# ATmega8A register map
Vendor: Atmel; File version: 1.0
CPU: other r0p0, little endian, no MPU, no FPU, 4 interrupt priority bits
Registers are 8-bit, read-write, reset 0x0 unless marked. A register's access mark holds for its fields unless they carry their own. Offsets are from the block's base; [hi:lo] are bit positions; {n}, {i} and the like mark numbered series; 'fields as' and 'values as' point back to an identical list.

## EEPROM
Base 0x0000003C
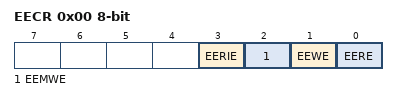
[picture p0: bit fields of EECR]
0x00 EECR — EEPROM Control Register
  [3] EERIE — EEPROM Ready Interrupt Enable
  [2] EEMWE — EEPROM Master Write Enable
  [1] EEWE — EEPROM Write Enable
  [0] EERE — EEPROM Read Enable
0x01 EEDR — EEPROM Data Register
0x02 EEAR 16-bit (reset mask 0xFF) — EEPROM Address Register Bytes

## EXINT — External Interrupts
Base 0x00000055
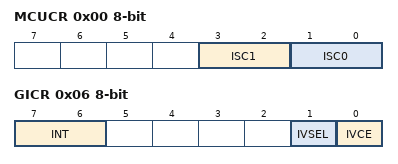
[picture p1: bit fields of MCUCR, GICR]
0x00 MCUCR — MCU Control Register
  [3:2] ISC1 — Interrupt Sense Control 1 Bits
    0=Low Level of INTX; 1=Any Logical Change of INTX; 2=Falling Edge of INTX; 3=Rising Edge of INTX
  [1:0] ISC0 — Interrupt Sense Control 0 Bits
    values as ISC1
0x05 GIFR — General Interrupt Flag Register
  [7:6] INTF — External Interrupt Flags
0x06 GICR — General Interrupt Control Register
  [7:6] INT — External Interrupt Request 1 Enable
  [1] IVSEL — Interrupt Vector Select
  [0] IVCE — Interrupt Vector Change Enable

## LOCKBIT — Lockbits
Base 0x00000000
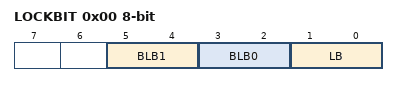
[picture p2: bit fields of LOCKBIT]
0x00 LOCKBIT
  [5:4] BLB1 — Boot Loader Protection Mode
    0=LPM_SPM_DISABLE (LPM and SPM prohibited in Boot Section); 1=LPM_DISABLE (LPM prohibited in Boot Section); 2=SPM_DISABLE (SPM prohibited in Boot Section); 3=NO_LOCK (No lock on SPM and LPM in Boot Section)
  [3:2] BLB0 — Boot Loader Protection Mode
    0=LPM_SPM_DISABLE (LPM and SPM prohibited in Application Section); 1=LPM_DISABLE (LPM prohibited in Application Section); 2=SPM_DISABLE (SPM prohibited in Application Section); 3=NO_LOCK (No lock on SPM and LPM in Application Section)
  [1:0] LB — Memory Lock
    0=PROG_VER_DISABLED (Further programming and verification disabled); 2=PROG_DISABLED (Further programming disabled); 3=NO_LOCK (No memory lock features enabled)

## PORTB — I/O Port
Base 0x00000036
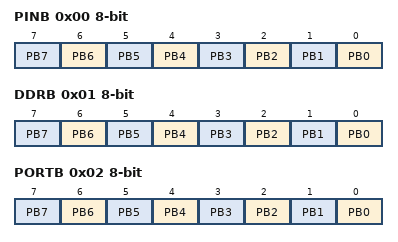
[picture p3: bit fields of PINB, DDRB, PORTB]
0x00 PINB — Port B Input Pins
  [n] PB{n} (n=0..7) — Pin B{n}
0x01 DDRB — Port B Data Direction Register
  [n] PB{n} (n=0..7) — Pin B{n}
0x02 PORTB — Port B Data Register
  [n] PB{n} (n=0..7) — Pin B{n}

## PORTC — I/O Port
Base 0x00000033
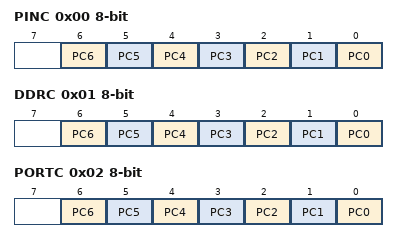
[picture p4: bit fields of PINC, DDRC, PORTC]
0x00 PINC — Port C Input Pins
  [n] PC{n} (n=0..6) — Pin C{n}
0x01 DDRC — Port C Data Direction Register
  [n] PC{n} (n=0..6) — Pin C{n}
0x02 PORTC — Port C Data Register
  [n] PC{n} (n=0..6) — Pin C{n}

## PORTD — I/O Port
Base 0x00000030
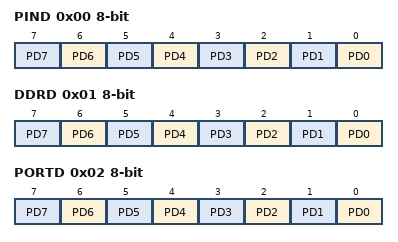
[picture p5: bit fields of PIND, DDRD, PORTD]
0x00 PIND — Port D Input Pins
  [n] PD{n} (n=0..7) — Pin D{n}
0x01 DDRD — Port D Data Direction Register
  [n] PD{n} (n=0..7) — Pin D{n}
0x02 PORTD — Port D Data Register
  [n] PD{n} (n=0..7) — Pin D{n}

## SPI — Serial Peripheral Interface
Base 0x0000002D
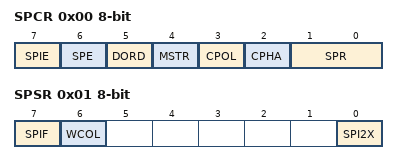
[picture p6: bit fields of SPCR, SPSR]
0x00 SPCR — SPI Control Register
  [7] SPIE — SPI Interrupt Enable
  [6] SPE — SPI Enable
  [5] DORD — Data Order
  [4] MSTR — Master/Slave Select
  [3] CPOL — Clock polarity
  [2] CPHA — Clock Phase
  [1:0] SPR — SPI Clock Rate Selects
    0=fosc/4; 1=fosc/16; 2=fosc/64; 3=fosc/128
0x01 SPSR — SPI Status Register
  [7] SPIF — SPI Interrupt Flag
  [6] WCOL — Write Collision Flag
  [0] SPI2X — Double SPI Speed Bit
0x02 SPDR — SPI Data Register

## TC0 — Timer/Counter, 8-bit
Base 0x00000052
0x00 TCNT0 — Timer Counter 0
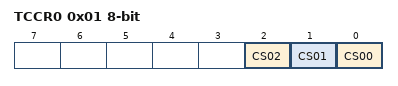
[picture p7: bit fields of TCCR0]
0x01 TCCR0 — Timer/Counter0 Control Register
  [2] CS02 — Clock Select0 bit 2
  [1] CS01 — Clock Select0 bit 1
  [0] CS00 — Clock Select0 bit 0
    0=No Clock Source (Stopped); 1=Running, No Prescaling
0x06 TIFR — Timer/Counter Interrupt Flag register
  [0] TOV0 — Timer/Counter0 Overflow Flag
0x07 TIMSK — Timer/Counter Interrupt Mask Register
  [0] TOIE0 — Timer/Counter0 Overflow Interrupt Enable

## TC1 — Timer/Counter, 16-bit
Base 0x00000046
0x00 ICR1 16-bit (reset mask 0xFF) — Timer/Counter1 Input Capture Register Bytes
0x02 OCR1B 16-bit (reset mask 0xFF) — Timer/Counter1 Output Compare Register Bytes
0x04 OCR1A 16-bit (reset mask 0xFF) — Timer/Counter1 Output Compare Register Bytes
0x06 TCNT1 16-bit (reset mask 0xFF) — Timer/Counter1 Bytes
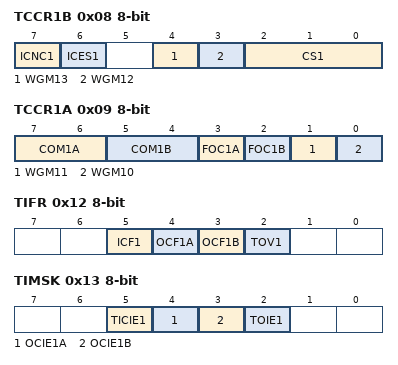
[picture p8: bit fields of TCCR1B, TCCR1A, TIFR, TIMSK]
0x08 TCCR1B — Timer/Counter1 Control Register B
  [7] ICNC1 — Input Capture 1 Noise Canceler
  [6] ICES1 — Input Capture 1 Edge Select
  [4] WGM13 — Waveform Generation Mode
  [3] WGM12 — Waveform Generation Mode
  [2:0] CS1 — Prescaler source of Timer/Counter 1
    0=No Clock Source (Stopped); 1=Running, No Prescaling; 2=Running, CLK/8; 3=Running, CLK/64; 4=Running, CLK/256; 5=Running, CLK/1024; 6=Running, ExtClk Tx Falling Edge; 7=Running, ExtClk Tx Rising Edge
0x09 TCCR1A — Timer/Counter1 Control Register A
  [7:6] COM1A — Compare Output Mode 1A, bits
  [5:4] COM1B — Compare Output Mode 1B, bits
  [3] FOC1A — Force Output Compare 1A
  [2] FOC1B — Force Output Compare 1B
  [1] WGM11 — Waveform Generation Mode
  [0] WGM10 — Waveform Generation Mode
0x12 TIFR — Timer/Counter Interrupt Flag register
  [5] ICF1 — Input Capture Flag 1
  [4] OCF1A — Output Compare Flag 1A
  [3] OCF1B — Output Compare Flag 1B
  [2] TOV1 — Timer/Counter1 Overflow Flag
0x13 TIMSK — Timer/Counter Interrupt Mask Register
  [5] TICIE1 — Timer/Counter1 Input Capture Interrupt Enable
  [4] OCIE1A — Timer/Counter1 Output CompareA Match Interrupt Enable
  [3] OCIE1B — Timer/Counter1 Output CompareB Match Interrupt Enable
  [2] TOIE1 — Timer/Counter1 Overflow Interrupt Enable

## TC2 — Timer/Counter, 8-bit Async
Base 0x00000042
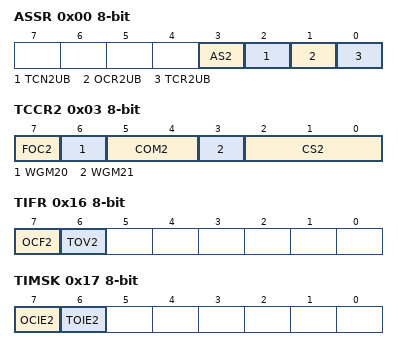
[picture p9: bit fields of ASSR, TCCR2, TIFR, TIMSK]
0x00 ASSR — Asynchronous Status Register
  [3] AS2 — Asynchronous Timer/counter2
  [2] TCN2UB — Timer/Counter2 Update Busy
  [1] OCR2UB — Output Compare Register2 Update Busy
  [0] TCR2UB — Timer/counter Control Register2 Update Busy
0x01 OCR2 — Timer/Counter2 Output Compare Register
0x02 TCNT2 — Timer/Counter2
0x03 TCCR2 — Timer/Counter2 Control Register
  [7] FOC2 — Force Output Compare
  [6] WGM20 — Waveform Genration Mode
    0=Normal; 1=CTC
  [5:4] COM2 — Compare Output Mode bits
  [3] WGM21 — Waveform Generation Mode
  [2:0] CS2 — Clock Select bits
    0=No Clock Source (Stopped); 1=Running, No Prescaling; 2=Running, CLK/8; 3=Running, CLK/32; 4=Running, CLK/64; 5=Running, CLK/128; 6=Running, CLK/256; 7=Running, CLK/1024
0x0E SFIOR — Special Function IO Register
  [1] PSR2 — Prescaler Reset Timer/Counter2
0x16 TIFR — Timer/Counter Interrupt Flag Register
  [7] OCF2 — Output Compare Flag 2
  [6] TOV2 — Timer/Counter2 Overflow Flag
0x17 TIMSK — Timer/Counter Interrupt Mask register
  [7] OCIE2 — Timer/Counter2 Output Compare Match Interrupt Enable
  [6] TOIE2 — Timer/Counter2 Overflow Interrupt Enable

## TWI — Two Wire Serial Interface
Base 0x00000020
0x00 TWBR — TWI Bit Rate register
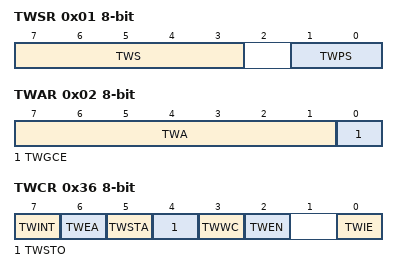
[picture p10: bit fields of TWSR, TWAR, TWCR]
0x01 TWSR — TWI Status Register
  [7:3] TWS — TWI Status
  [1:0] TWPS — TWI Prescaler
    0=1; 1=4; 2=16; 3=64
0x02 TWAR — TWI (Slave) Address register
  [7:1] TWA — TWI (Slave) Address register Bits
  [0] TWGCE — TWI General Call Recognition Enable Bit
0x03 TWDR — TWI Data register
0x36 TWCR — TWI Control Register
  [7] TWINT — TWI Interrupt Flag
  [6] TWEA — TWI Enable Acknowledge Bit
  [5] TWSTA — TWI Start Condition Bit
  [4] TWSTO — TWI Stop Condition Bit
  [3] TWWC — TWI Write Collition Flag
  [2] TWEN — TWI Enable Bit
  [0] TWIE — TWI Interrupt Enable

## USART
Base 0x00000029
0x00 UBRRL — USART Baud Rate Register Low Byte
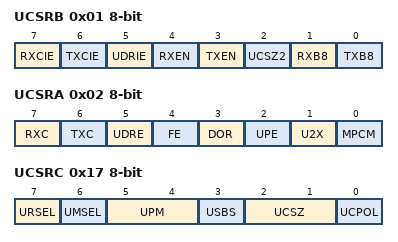
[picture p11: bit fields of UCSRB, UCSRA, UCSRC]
0x01 UCSRB — USART Control and Status Register B
  [7] RXCIE — RX Complete Interrupt Enable
  [6] TXCIE — TX Complete Interrupt Enable
  [5] UDRIE — USART Data register Empty Interrupt Enable
  [4] RXEN — Receiver Enable
  [3] TXEN — Transmitter Enable
  [2] UCSZ2 — Character Size
  [1] RXB8 — Receive Data Bit 8
  [0] TXB8 — Transmit Data Bit 8
0x02 UCSRA — USART Control and Status Register A
  [7] RXC — USART Receive Complete
  [6] TXC — USART Transmitt Complete
  [5] UDRE — USART Data Register Empty
  [4] FE — Framing Error
  [3] DOR — Data overRun
  [2] UPE — Parity Error
  [1] U2X — Double the USART transmission speed
  [0] MPCM — Multi-processor Communication Mode
0x03 UDR — USART I/O Data Register
0x17 UBRRH — USART Baud Rate Register Hight Byte
0x17 UCSRC — USART Control and Status Register C
  [7] URSEL — Register Select
  [6] UMSEL — USART Mode Select
    0=Asynchronous Operation; 1=Synchronous Operation
  [5:4] UPM — Parity Mode Bits
    0=Disabled; 2=Enabled, Even Parity; 3=Enabled, Odd Parity
  [3] USBS — Stop Bit Select
    0=1-bit; 1=2-bit
  [2:1] UCSZ — Character Size
  [0] UCPOL — Clock Polarity

## WDT — Watchdog Timer
Base 0x00000041
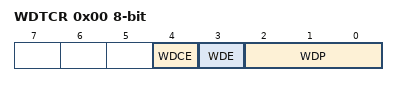
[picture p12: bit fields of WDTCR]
0x00 WDTCR — Watchdog Timer Control Register
  [4] WDCE — Watchdog Change Enable
  [3] WDE — Watch Dog Enable
  [2:0] WDP — Watch Dog Timer Prescaler bits
    0=Oscillator Cycles 16K; 1=Oscillator Cycles 32K; 2=Oscillator Cycles 64K; 3=Oscillator Cycles 128K; 4=Oscillator Cycles 256K; 5=Oscillator Cycles 512K; 6=Oscillator Cycles 1024K; 7=Oscillator Cycles 2048K
